# AS32x601 register map
File version: 1.0
CPU: RISC-V, little endian
Registers are 32-bit, read-write, reset 0x0 unless marked. A register's access mark holds for its fields unless they carry their own. Offsets are from the block's base; [hi:lo] are bit positions.

## I2C0 — Inter-Integrated Circuit 0
Base 0x50004000
Same registers: I2C1 0x50005000, I2C2 0x51003000, I2C3 0x51004000
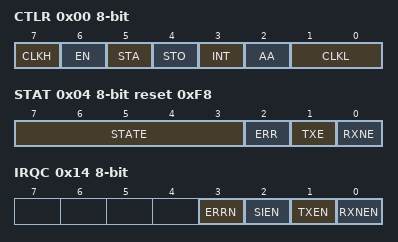
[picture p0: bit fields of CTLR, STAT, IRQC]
0x00 CTLR 8-bit — I2C Control Register
  [7] CLKH — Serial clock rate
  [6] EN — Enable bit
  [5] STA — The START flag
  [4] STO — The STOP flag
  [3] INT — The Serial Interrupt flag
  [2] AA — The Assert Acknowledge flag
  [1:0] CLKL — Serial clock rate
0x04 STAT 8-bit ro reset 0xF8 — I2C Status Register
  [7:3] STATE — Running state
  [2] ERR — Transmission error status
  [1] TXE — Send idle status
  [0] RXNE — Receive idle status
0x08 DATA 8-bit — I2C Data Register
  [7:0] DATA — Serial data
0x0C ADDR 8-bit — I2C Slave Address Register
  [7:1] ADDR — Slave Address
0x10 DIV_L 8-bit reset 0x2 — I2C Frequency division coefficient register low
  [7:0] DIV — Division factor
0x14 IRQC 8-bit — I2C Interrupt control register
  [3] ERRN — Transmission error interrupt enable
  [2] SIEN — Sequential operation interrupt enable
  [1] TXEN — Send idle interrupt enable
  [0] RXNEN — Receive idle interrupt enable
0x18 DIV_H 8-bit — I2C Frequency division coefficient register high
  [7:0] DIV — Division factor

## SPI0 — SPI Controller 0
Base 0x50001000
Same registers: SPI1 0x50002000, SPI2 0x50003000, SPI3 0x51000000, SPI4 0x51001000, SPI5 0x51002000
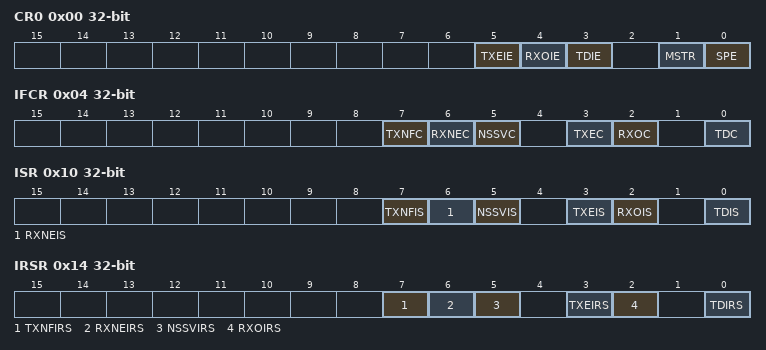
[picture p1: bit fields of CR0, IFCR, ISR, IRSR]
0x00 CR0 — SPI Control register 0
  [5] TXEIE — Tx buffer empty interrupt enable
  [4] RXOIE — Rx buffer overflow interrupt enable
  [3] TDIE — Tx done interrupt enable
  [1] MSTR — Select the master/slave mode
  [0] SPE — Enable SPI
0x04 IFCR wo — SPI Interrupt clear register
  [7] TXNFC — Tx buffer non-full interrupt clear
  [6] RXNEC — Rx buffer non-empty interrupt clear
  [5] NSSVC — NSS Voh interrupt clear
  [3] TXEC — Tx buffer empty interrupt clear
  [2] RXOC — Rx buffer overflow interrupt clear
  [0] TDC — Tx done interrupt clear
0x08 RXDR ro — SPI Receive data register
  [31:0] RXDR — Receive data
0x0C TXDR wo — SPI Transmit data register
  [31:0] TXDR — Transmit data
0x10 ISR ro — SPI Interrupt status register
  [7] TXNFIS — Tx buffer non-full interrupt
  [6] RXNEIS — Rx buffer non-empty interrupt
  [5] NSSVIS — The chip selection signal is low interrupt
  [3] TXEIS — Data in the send buffer is not available
  [2] RXOIS — Receive buffer data overflow
  [0] TDIS — The last frame has been sent
0x14 IRSR ro — SPI Interrupt the raw status register
  [7] TXNFIRS — Tx buffer non-full interrupt raw status
  [6] RXNEIRS — Rx buffer non-empty interrupt raw status
  [5] NSSVIRS — NSS Voh interrupt raw status
  [3] TXEIRS — Tx buffer empty interrupt raw status
  [2] RXOIRS — Rx buffer overflow interrupt raw status
  [0] TDIRS — Tx done interrupt raw status
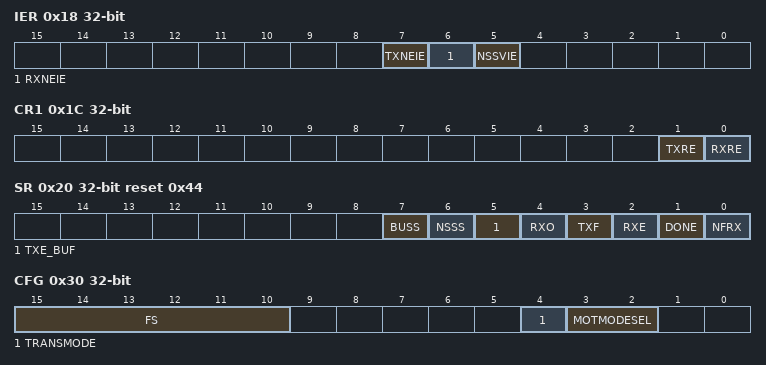
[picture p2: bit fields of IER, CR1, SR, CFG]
0x18 IER — SPI Control register 1
  [7] TXNEIE — Tx buffer non-full interrupt enable
  [6] RXNEIE — Rx buffer non-empty interrupt enable
  [5] NSSVIE — NSS Voh interrupt enable
0x1C CR1 wo — SPI Command buffer reset control register
  [1] TXRE — Reset transmit buffer
  [0] RXRE — Reset receive buffer
0x20 SR ro reset 0x44 — SPI Status register
  [7] BUSS — SPI is still transmitting data
  [6] NSSS — The state of select slave
  [5] TXE_BUF — Tx buffer is empty
  [4] RXO — Rx buffer is overflow
  [3] TXF — Tx buffer is full
  [2] RXE — Rx buffer is empty
  [1] DONE — No request for receiving and sending
  [0] NFRX — NSS is effective, the next frame in the receiving buffer is received for the first time
0x24 SSR — SPI Slave select register
  [3:0] SSR — Slave selection
0x28 TXEDR — SPI End of send data register
  [31:0] TXEDR — Transmitter last frame
0x2C CLKCR reset 0x7 — SPI Clock division configuration register
  [7:0] CLKCR — Frequency divider
0x30 CFG — SPI Mode register
  [15:10] FS — SPI frame size
  [4] TRANSMODE — Transmission mode
  [3:2] MOTMODESEL — Motorola mode selection
